# CEC1736_S0_2HW register map
Vendor: Microchip
Registers are 32-bit, read-write, reset 0x0 unless marked. A register's access mark holds for its fields unless they carry their own. Addresses are absolute, and some are shared; only a register's first bit layout is shown; [hi:lo] are bit positions; lines under a group give offsets from that group; {n}, {i} and the like mark numbered series; 'fields as' and 'values as' point back to an identical list.

## ECIA
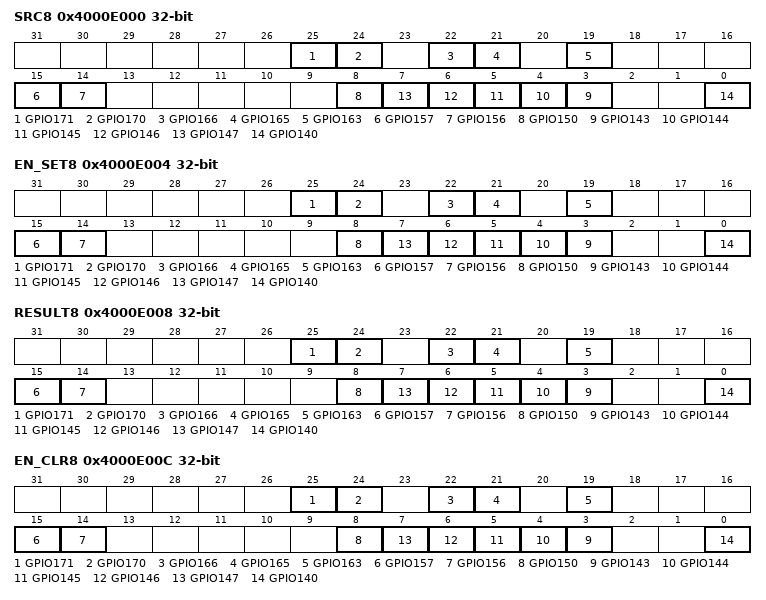
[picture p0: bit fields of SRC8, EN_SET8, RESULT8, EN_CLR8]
0x4000E000 SRC8
  [25] GPIO171, [24] GPIO170, [22] GPIO166, [21] GPIO165, [19] GPIO163, [15] GPIO157, [14] GPIO156, [8] GPIO150, [n-140] GPIO{n} (n=143..147), [0] GPIO140
0x4000E004 EN_SET8
  fields as SRC8
0x4000E008 RESULT8 ro
  fields as SRC8
0x4000E00C EN_CLR8
  fields as SRC8
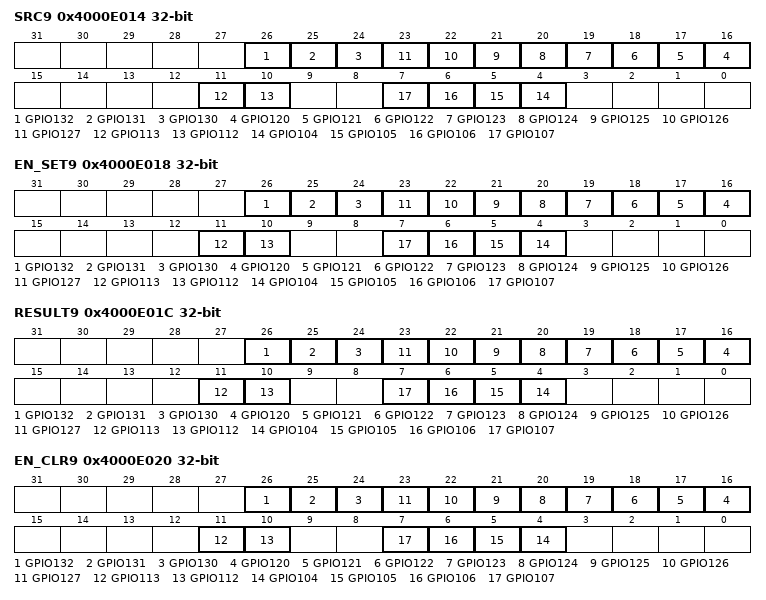
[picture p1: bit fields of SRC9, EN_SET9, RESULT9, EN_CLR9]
0x4000E014 SRC9
  [26] GPIO132, [25] GPIO131, [24] GPIO130, [n-104] GPIO{n} (n=120..127), [11] GPIO113, [10] GPIO112, [n-100] GPIO{n} (n=104..107)
0x4000E018 EN_SET9
  fields as SRC9
0x4000E01C RESULT9 ro
  fields as SRC9
0x4000E020 EN_CLR9
  fields as SRC9
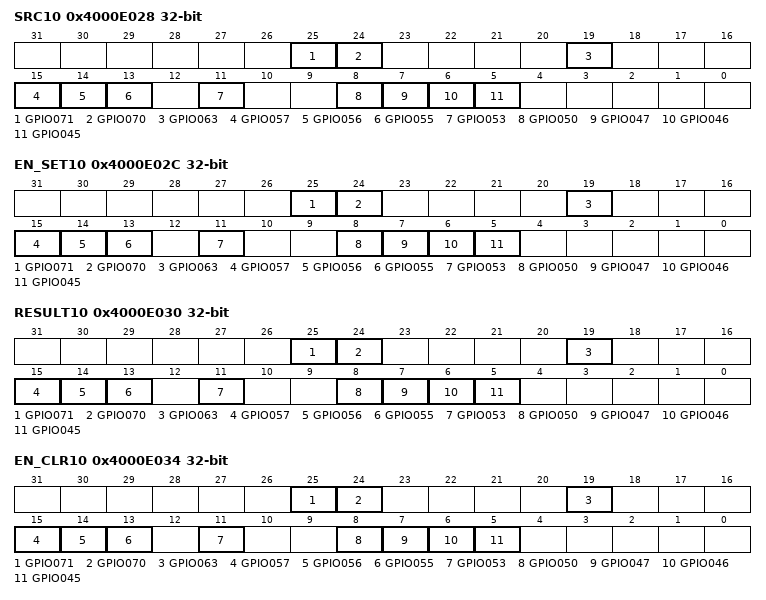
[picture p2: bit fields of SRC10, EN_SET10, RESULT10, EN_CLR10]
0x4000E028 SRC10
  [25] GPIO071
  [24] GPIO070
  [19] GPIO063 — GPIO 060
  [15] GPIO057
  [14] GPIO056
  [13] GPIO055
  [11] GPIO053
  [8] GPIO050
  [7] GPIO047
  [6] GPIO046
  [5] GPIO045
0x4000E02C EN_SET10
  fields as SRC10
0x4000E030 RESULT10 ro
  fields as SRC10
0x4000E034 EN_CLR10
  fields as SRC10
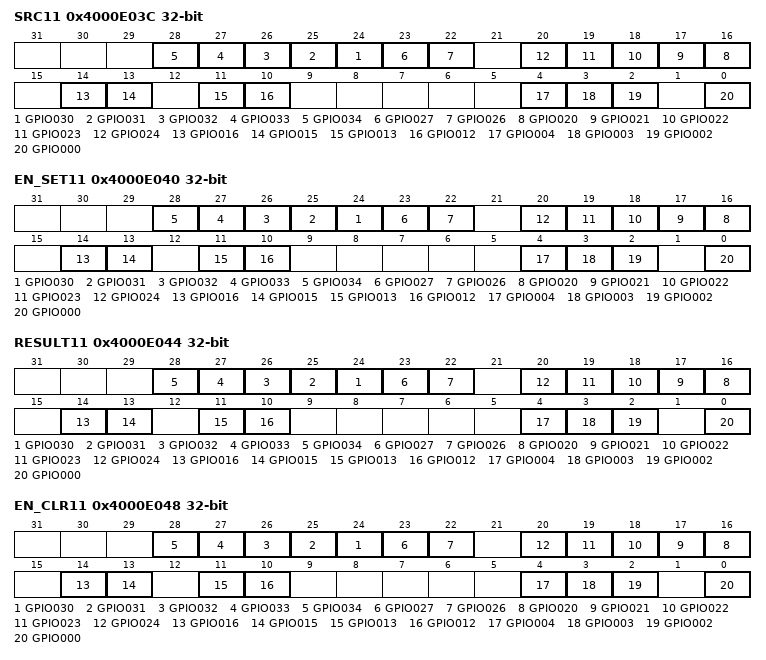
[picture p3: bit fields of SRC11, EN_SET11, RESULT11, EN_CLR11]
0x4000E03C SRC11
  [n-6] GPIO{n:03} (n=30..34), [23] GPIO027, [22] GPIO026, [n-4] GPIO{n:03} (n=20..24), [14] GPIO016, [13] GPIO015, [11] GPIO013, [10] GPIO012, [4] GPIO004, [3] GPIO003, [2] GPIO002, [0] GPIO000
0x4000E040 EN_SET11
  fields as SRC11
0x4000E044 RESULT11 ro
  fields as SRC11
0x4000E048 EN_CLR11
  fields as SRC11
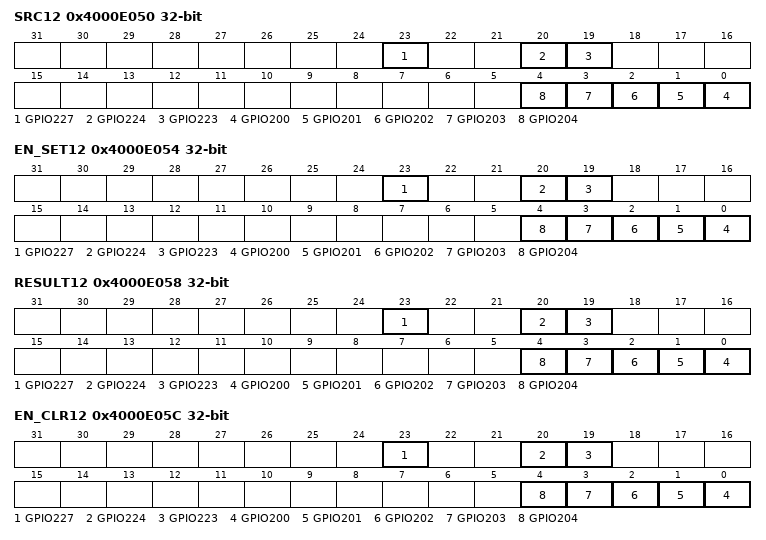
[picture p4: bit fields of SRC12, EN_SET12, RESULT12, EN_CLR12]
0x4000E050 SRC12
  [23] GPIO227, [20] GPIO224, [19] GPIO223, [n-200] GPIO{n} (n=200..204)
0x4000E054 EN_SET12
  fields as SRC12
0x4000E058 RESULT12 ro
  fields as SRC12
0x4000E05C EN_CLR12
  fields as SRC12
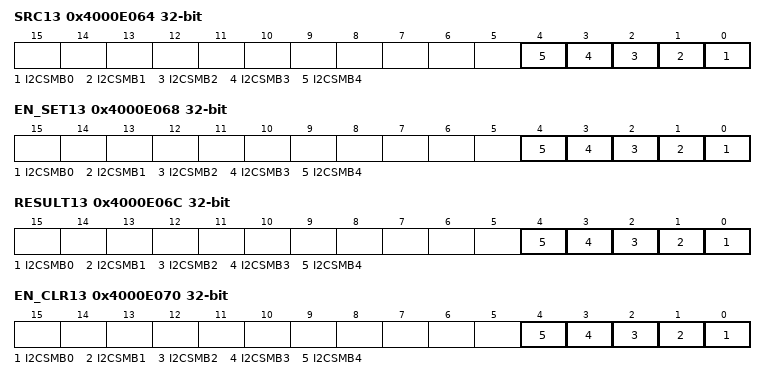
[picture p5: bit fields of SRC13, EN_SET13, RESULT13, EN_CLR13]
0x4000E064 SRC13
  [n] I2CSMB{n} (n=0..4)
0x4000E068 EN_SET13
  [n] I2CSMB{n} (n=0..4)
0x4000E06C RESULT13 ro
  [n] I2CSMB{n} (n=0..4)
0x4000E070 EN_CLR13
  [n] I2CSMB{n} (n=0..4)
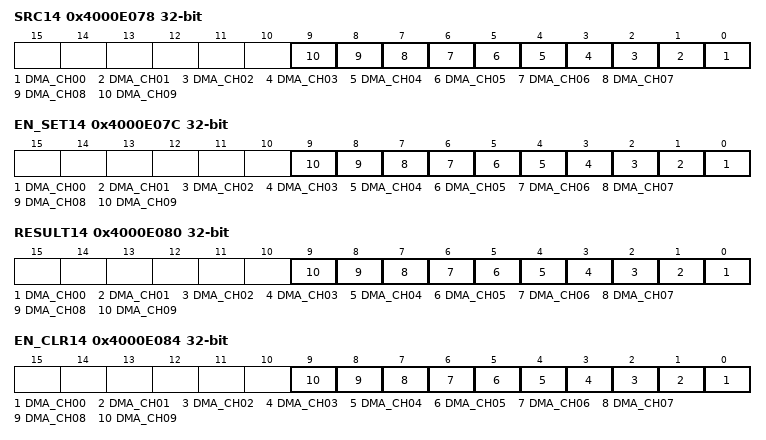
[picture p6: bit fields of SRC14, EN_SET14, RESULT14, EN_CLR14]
0x4000E078 SRC14
  [n] DMA_CH{n:02} (n=0..9)
0x4000E07C EN_SET14
  [n] DMA_CH{n:02} (n=0..9)
0x4000E080 RESULT14 ro
  [n] DMA_CH{n:02} (n=0..9)
0x4000E084 EN_CLR14
  [n] DMA_CH{n:02} (n=0..9)
0x4000E08C SRC15
  [0] UART0
0x4000E090 EN_SET15
  [0] UART0
0x4000E094 RESULT15 ro
  [0] UART0
0x4000E098 EN_CLR15
  [0] UART0
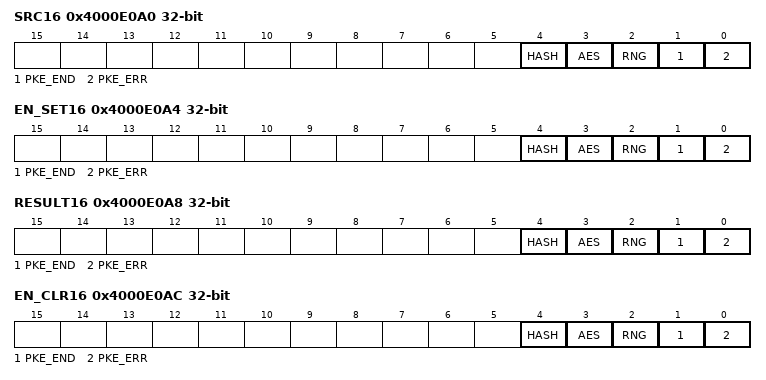
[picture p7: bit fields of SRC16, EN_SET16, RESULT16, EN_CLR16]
0x4000E0A0 SRC16
  [4] HASH, [3] AES, [2] RNG, [1] PKE_END, [0] PKE_ERR
0x4000E0A4 EN_SET16
  [4] HASH, [3] AES, [2] RNG, [1] PKE_END, [0] PKE_ERR
0x4000E0A8 RESULT16 ro
  [4] HASH, [3] AES, [2] RNG, [1] PKE_END, [0] PKE_ERR
0x4000E0AC EN_CLR16
  [4] HASH, [3] AES, [2] RNG, [1] PKE_END, [0] PKE_ERR
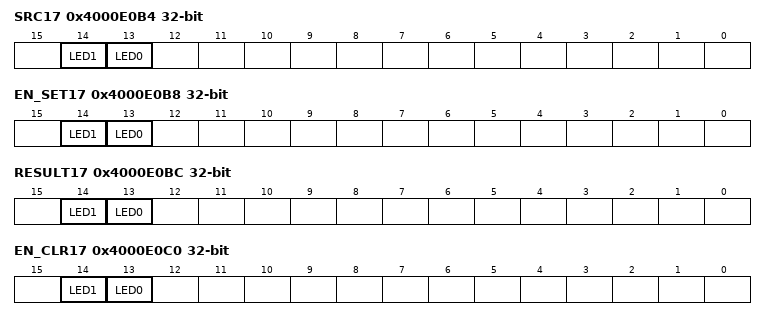
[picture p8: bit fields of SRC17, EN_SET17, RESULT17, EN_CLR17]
0x4000E0B4 SRC17
  [14] LED1 — Breating LED1
  [13] LED0 — Breating LED0
0x4000E0B8 EN_SET17
  [14] LED1 — Breating LED1
  [13] LED0 — Breating LED0
0x4000E0BC RESULT17 ro
  [14] LED1 — Breating LED1
  [13] LED0 — Breating LED0
0x4000E0C0 EN_CLR17
  [14] LED1 — Breating LED1
  [13] LED0 — Breating LED0
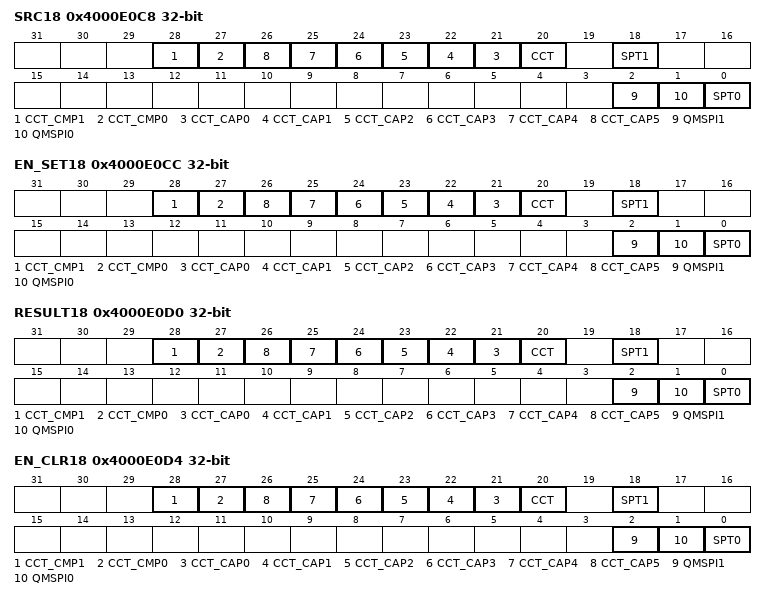
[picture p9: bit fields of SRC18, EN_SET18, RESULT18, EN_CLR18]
0x4000E0C8 SRC18
  [28] CCT_CMP1, [27] CCT_CMP0, [n+21] CCT_CAP{n} (n=0..5), [20] CCT, [18] SPT1, [2] QMSPI1, [1] QMSPI0, [0] SPT0
0x4000E0CC EN_SET18
  fields as SRC18
0x4000E0D0 RESULT18 ro
  fields as SRC18
0x4000E0D4 EN_CLR18
  fields as SRC18
0x4000E0DC SRC19
0x4000E0E0 EN_SET19
0x4000E0E4 RESULT19 ro
0x4000E0E8 EN_CLR19
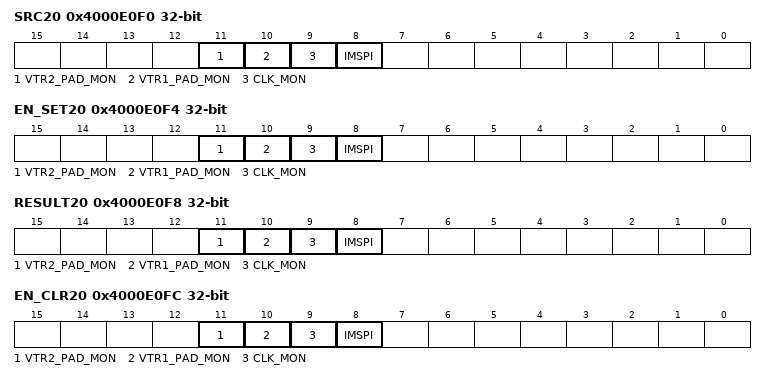
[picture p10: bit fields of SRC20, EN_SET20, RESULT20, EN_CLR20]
0x4000E0F0 SRC20
  [11] VTR2_PAD_MON, [10] VTR1_PAD_MON, [9] CLK_MON, [8] IMSPI
0x4000E0F4 EN_SET20
  [11] VTR2_PAD_MON, [10] VTR1_PAD_MON, [9] CLK_MON, [8] IMSPI
0x4000E0F8 RESULT20 ro
  [11] VTR2_PAD_MON, [10] VTR1_PAD_MON, [9] CLK_MON, [8] IMSPI
0x4000E0FC EN_CLR20
  [11] VTR2_PAD_MON, [10] VTR1_PAD_MON, [9] CLK_MON, [8] IMSPI
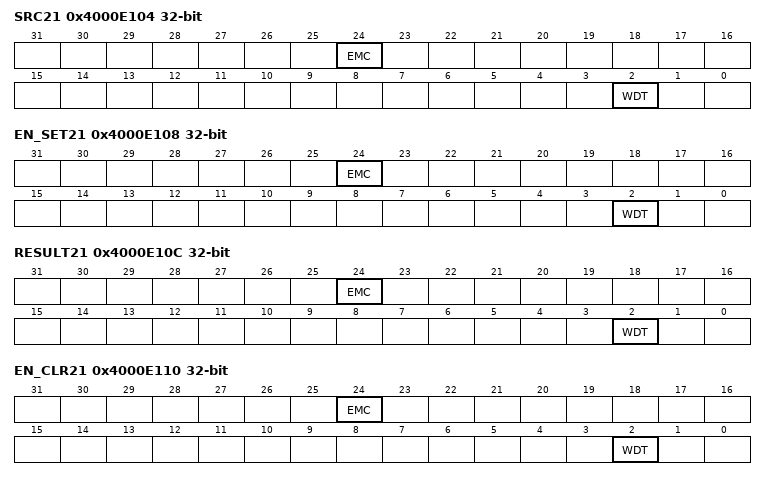
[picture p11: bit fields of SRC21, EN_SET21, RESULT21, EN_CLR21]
0x4000E104 SRC21
  [24] EMC, [2] WDT
0x4000E108 EN_SET21
  [24] EMC, [2] WDT
0x4000E10C RESULT21 ro
  [24] EMC, [2] WDT
0x4000E110 EN_CLR21
  [24] EMC, [2] WDT
0x4000E118 SRC22
0x4000E11C EN_SET22
0x4000E120 RESULT22 ro
0x4000E124 EN_CLR22
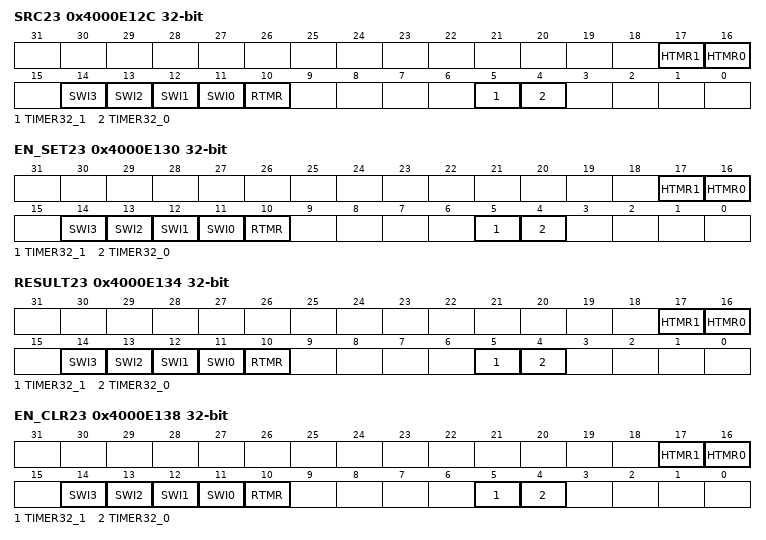
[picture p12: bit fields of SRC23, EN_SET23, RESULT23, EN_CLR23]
0x4000E12C SRC23
  [17] HTMR1, [16] HTMR0, [n+11] SWI{n} (n=0..3), [10] RTMR, [5] TIMER32_1, [4] TIMER32_0
0x4000E130 EN_SET23
  fields as SRC23
0x4000E134 RESULT23 ro
  fields as SRC23
0x4000E138 EN_CLR23
  fields as SRC23
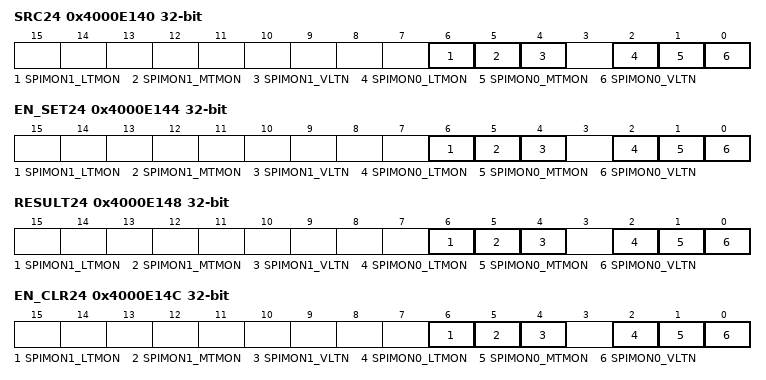
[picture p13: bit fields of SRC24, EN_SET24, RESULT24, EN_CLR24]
0x4000E140 SRC24
  [6] SPIMON1_LTMON, [5] SPIMON1_MTMON, [4] SPIMON1_VLTN, [2] SPIMON0_LTMON, [1] SPIMON0_MTMON, [0] SPIMON0_VLTN
0x4000E144 EN_SET24
  fields as SRC24
0x4000E148 RESULT24 ro
  fields as SRC24
0x4000E14C EN_CLR24
  fields as SRC24
0x4000E154 SRC25
0x4000E158 EN_SET25
0x4000E15C RESULT25 ro
0x4000E160 EN_CLR25
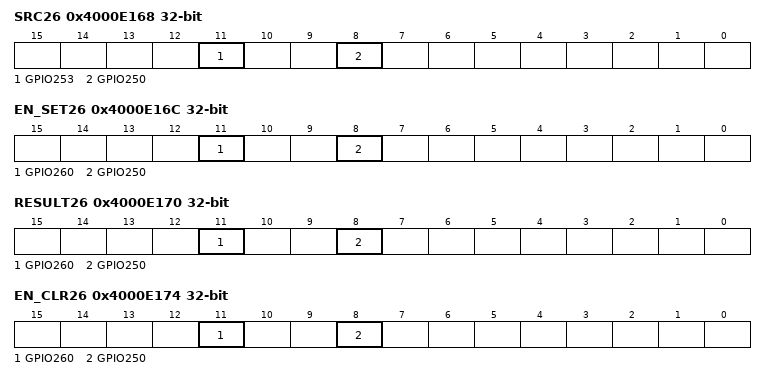
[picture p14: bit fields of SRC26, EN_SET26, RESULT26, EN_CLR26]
0x4000E168 SRC26
  [11] GPIO253, [8] GPIO250
0x4000E16C EN_SET26
  [11] GPIO260, [8] GPIO250
0x4000E170 RESULT26 ro
  [11] GPIO260, [8] GPIO250
0x4000E174 EN_CLR26
  [11] GPIO260, [8] GPIO250
0x4000E200 BLK_EN_SET
  [30:0] VTOR_EN_SET — Each GIRQx bit can be individually enabled to assert an interrupt event. Reads always return the current value of the internal GIRQX_ENABLE bit. The state of the GIRQX_ENABLE bit is determined by the corresponding GIRQX_ENABLE_SET bit and the GIRQX_ENABLE_CLEAR bit. (0=disabled, 1=enabled) (R/WS) 1=Interrupts in the GIRQx Source Register may be enabled 0=No effect.
0x4000E204 BLK_EN_CLR
  [30:0] VTOR_EN_CLR — Each GIRQx bit can be individually disabled to inhibit an interrupt event. Reads always return the current value of the internal GIRQX_ENABLE bit. The state of the GIRQX_ENABLE bit is determined by the corresponding GIRQX_ENABLE_SET bit and the GIRQX_ENABLE_CLEAR bit. (0=disabled, 1=enabled) (R/WC) 1=All interrupts in the GIRQx Source Register are disabled 0=No effect.
0x4000E208 BLK_IRQ_VTOR ro
  [24:0] VTOR — Each bit in this field reports the status of the group GIRQ interrupt assertion to the NVIC. If the GIRQx interrupt is disabled as a group, by the Block Enable Clear Register, then the corresponding bit will be '0'b and no interrupt will be asserted.
